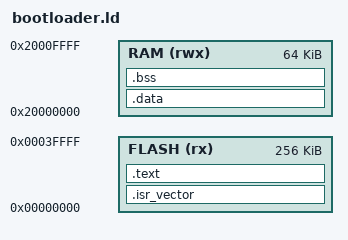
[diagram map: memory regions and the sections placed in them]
ENTRY(_reset_handler)

MEMORY {
  FLASH (rx) : ORIGIN = 0x00000000, LENGTH = 256K
  RAM   (rwx): ORIGIN = 0x20000000, LENGTH = 64K
}

_stack_top = ORIGIN(RAM) + LENGTH(RAM);

SECTIONS {
  .isr_vector : {
    KEEP(*(.isr_vector))
  } > FLASH

  .text : {
    *(.text*)
    *(.rodata*)
  } > FLASH

  .data : {
    *(.data*)
  } > RAM

  .bss : {
    *(.bss*)
    *(COMMON)
  } > RAM
}

